AUTOSAR XML (schema 4-0-3)
standard types defined: Boolean, UInt32
package /AUTOSAR_Platform/DataConstrs
  range DC_Boolean: raw 0..1
package /PATAC/MSM/ComponentTypes
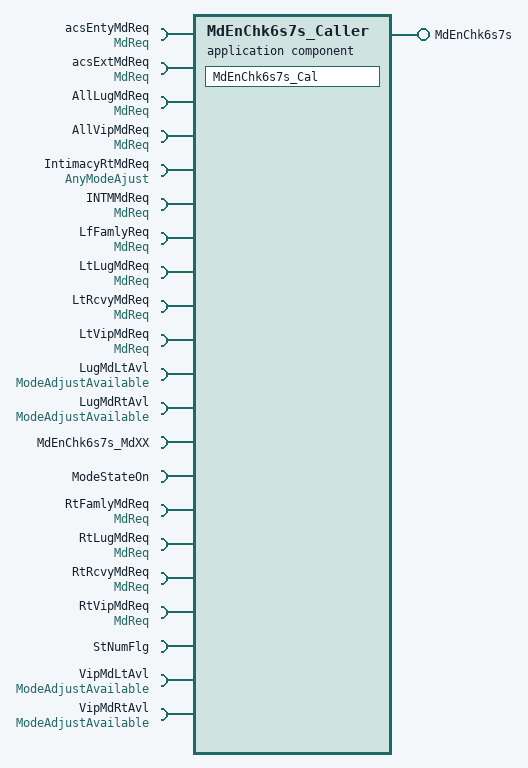
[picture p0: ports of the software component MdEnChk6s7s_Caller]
  application sw component type MdEnChk6s7s_Caller
    provide port MdEnChk6s7s: server-com-spec{operation=MdEnChk6s7s/Cal, queue-length=1}, provided-interface=MdEnChk6s7s
    21 x require port:
      acsEntyMdReq: nonqueued-receiver-com-spec{data-element=MdReq/Val, filter=data-filter-type=ALWAYS, init-value=0}, required-interface=MdReq
      acsExtMdReq: nonqueued-receiver-com-spec{data-element=MdReq/Val, filter=data-filter-type=ALWAYS, init-value=0}, required-interface=MdReq
      AllLugMdReq: nonqueued-receiver-com-spec{data-element=MdReq/Val, filter=data-filter-type=ALWAYS, init-value=0}, required-interface=MdReq
      AllVipMdReq: nonqueued-receiver-com-spec{data-element=MdReq/Val, filter=data-filter-type=ALWAYS, init-value=0}, required-interface=MdReq
      IntimacyRtMdReq: nonqueued-receiver-com-spec{data-element=AnyModeAjust/Val, filter=data-filter-type=ALWAYS, init-value=0}, required-interface=AnyModeAjust
      INTMMdReq: nonqueued-receiver-com-spec{data-element=MdReq/Val, filter=data-filter-type=ALWAYS, init-value=0}, required-interface=MdReq
      LfFamlyReq: nonqueued-receiver-com-spec{data-element=MdReq/Val, filter=data-filter-type=ALWAYS, init-value=0}, required-interface=MdReq
      LtLugMdReq: nonqueued-receiver-com-spec{data-element=MdReq/Val, filter=data-filter-type=ALWAYS, init-value=0}, required-interface=MdReq
      LtRcvyMdReq: nonqueued-receiver-com-spec{data-element=MdReq/Val, filter=data-filter-type=ALWAYS, init-value=0}, required-interface=MdReq
      LtVipMdReq: nonqueued-receiver-com-spec{data-element=MdReq/Val, filter=data-filter-type=ALWAYS, init-value=0}, required-interface=MdReq
      LugMdLtAvl: nonqueued-receiver-com-spec{data-element=ModeAdjustAvailable/Val, filter=data-filter-type=ALWAYS, init-value=0}, required-interface=ModeAdjustAvailable
      LugMdRtAvl: nonqueued-receiver-com-spec{data-element=ModeAdjustAvailable/Val, filter=data-filter-type=ALWAYS, init-value=0}, required-interface=ModeAdjustAvailable
      MdEnChk6s7s_MdXX: client-com-spec=MdEnChk6s7s_MdXX/Cal, required-interface=MdEnChk6s7s_MdXX
      ModeStateOn: nonqueued-receiver-com-spec{data-element=ModeStateOn/Val, filter=data-filter-type=ALWAYS, init-value=0}, required-interface=ModeStateOn
      RtFamlyMdReq: nonqueued-receiver-com-spec{data-element=MdReq/Val, filter=data-filter-type=ALWAYS, init-value=0}, required-interface=MdReq
      RtLugMdReq: nonqueued-receiver-com-spec{data-element=MdReq/Val, filter=data-filter-type=ALWAYS, init-value=0}, required-interface=MdReq
      RtRcvyMdReq: nonqueued-receiver-com-spec{data-element=MdReq/Val, filter=data-filter-type=ALWAYS, init-value=0}, required-interface=MdReq
      RtVipMdReq: nonqueued-receiver-com-spec{data-element=MdReq/Val, filter=data-filter-type=ALWAYS, init-value=0}, required-interface=MdReq
      StNumFlg: required-interface=StNumFlg
        required-com-specs:
          data-element=Is4s, filter=data-filter-type=ALWAYS, init-value=0
          data-element=Is6s, filter=data-filter-type=ALWAYS, init-value=0
          data-element=Is6s7s, filter=data-filter-type=ALWAYS, init-value=0
          data-element=Is7s, filter=data-filter-type=ALWAYS, init-value=0
      VipMdLtAvl: nonqueued-receiver-com-spec{data-element=ModeAdjustAvailable/Val, filter=data-filter-type=ALWAYS, init-value=0}, required-interface=ModeAdjustAvailable
      VipMdRtAvl: nonqueued-receiver-com-spec{data-element=ModeAdjustAvailable/Val, filter=data-filter-type=ALWAYS, init-value=0}, required-interface=ModeAdjustAvailable
    behavior MdEnChk6s7s_Caller_InternalBehavior
      operation invoked event OIT_MdEnChk6s7s_Cal_MdEnChk6s7s_Cal: start-on-event=MdEnChk6s7s_Cal, operation=MdEnChk6s7s.Cal
      runnable MdEnChk6s7s_Cal
        data-receive-point-by-arguments:
          23 x access:
            REC_acsEntyMdReq_Val: accessed-variable=acsEntyMdReq.Val
            REC_acsExtMdReq_Val: accessed-variable=acsExtMdReq.Val
            REC_AllLugMdReq_Val: accessed-variable=AllLugMdReq.Val
            REC_AllVipMdReq_Val: accessed-variable=AllVipMdReq.Val
            REC_IntimacyRtMdReq_Val: accessed-variable=IntimacyRtMdReq.Val
            REC_INTMMdReq_Val: accessed-variable=INTMMdReq.Val
            REC_LfFamlyReq_Val: accessed-variable=LfFamlyReq.Val
            REC_LtLugMdReq_Val: accessed-variable=LtLugMdReq.Val
            REC_LtRcvyMdReq_Val: accessed-variable=LtRcvyMdReq.Val
            REC_LtVipMdReq_Val: accessed-variable=LtVipMdReq.Val
            REC_LugMdLtAvl_Val: accessed-variable=LugMdLtAvl.Val
            REC_LugMdRtAvl_Val: accessed-variable=LugMdRtAvl.Val
            REC_ModeStateOn_Val: accessed-variable=ModeStateOn.Val
            REC_RtFamlyMdReq_Val: accessed-variable=RtFamlyMdReq.Val
            REC_RtLugMdReq_Val: accessed-variable=RtLugMdReq.Val
            REC_RtRcvyMdReq_Val: accessed-variable=RtRcvyMdReq.Val
            REC_RtVipMdReq_Val: accessed-variable=RtVipMdReq.Val
            REC_StNumFlg_Is4s: accessed-variable=StNumFlg.Is4s
            REC_StNumFlg_Is6s: accessed-variable=StNumFlg.Is6s
            REC_StNumFlg_Is6s7s: accessed-variable=StNumFlg.Is6s7s
            REC_StNumFlg_Is7s: accessed-variable=StNumFlg.Is7s
            REC_VipMdLtAvl_Val: accessed-variable=VipMdLtAvl.Val
            REC_VipMdRtAvl_Val: accessed-variable=VipMdRtAvl.Val
        sync call SC_MdEnChk6s7s_MdXX_Cal: operation=MdEnChk6s7s_MdXX.Cal, timeout=0
  swc implementation MdEnChk6s7s_Caller_Implementation: behavior=MdEnChk6s7s_Caller_InternalBehavior
    code-descriptors:
      code Default: artifact-descriptors=autosar-engineering-object={short-label=Default, category=SWSRC}
package /PATAC/MSM/ModeAdjust/PortInterface
  client server interface MdEnChk6s7s
    operation Cal
  client server interface MdEnChk6s7s_MdXX
    operation Cal  # StNun: 0 :4s 1:6s 2:7s 3:4sp
      5 x arg, all with direction=IN, server-argument-impl-policy=USE-ARGUMENT-TYPE:
        Req: type=DataTypes/Boolean
        ChkBsyBit: type=UInt32
        SetEnBit: type=UInt32
        SetBsyBit: type=UInt32
        MdAvl: type=DataTypes/Boolean
  5 x sender receiver interface:
    AnyModeAjust: invalidation-policy{data-element=AnyModeAjust/Val, handle-invalid=DONT-INVALIDATE}
      data Val: type=Implementation/Boolean
    MdReq: invalidation-policy{data-element=MdReq/Val, handle-invalid=DONT-INVALIDATE}
      data Val: type=Implementation/Boolean
    ModeAdjustAvailable: invalidation-policy{data-element=ModeAdjustAvailable/Val, handle-invalid=DONT-INVALIDATE}
      data Val: type=Implementation/Boolean
    ModeStateOn: invalidation-policy{data-element=ModeStateOn/Val, handle-invalid=DONT-INVALIDATE}
      data Val: type=Implementation/Boolean
    StNumFlg
      4 x data, all with type=Implementation/Boolean:
        Is4s
        Is6s
        Is6s7s
        Is7s
      invalidation-policys:
        data-element=Is7s, handle-invalid=DONT-INVALIDATE
        data-element=Is6s, handle-invalid=DONT-INVALIDATE
        data-element=Is4s, handle-invalid=DONT-INVALIDATE
        data-element=Is6s7s, handle-invalid=DONT-INVALIDATE
